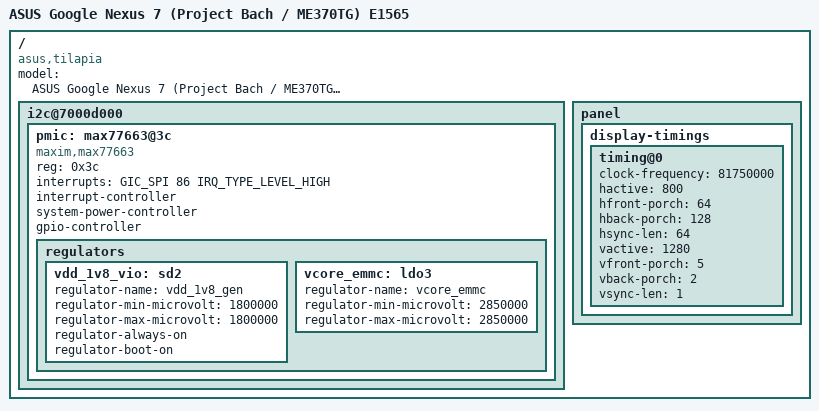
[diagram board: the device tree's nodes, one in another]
// SPDX-License-Identifier: GPL-2.0
/dts-v1/;

#include "tegra30-asus-grouper-common.dtsi"

/ {
	model = "ASUS Google Nexus 7 (Project Bach / ME370TG) E1565";
	compatible = "asus,tilapia", "nvidia,tegra30";

	i2c@7000d000 {
		pmic: max77663@3c {
			compatible = "maxim,max77663";
			reg = <0x3c>;

			interrupts = <GIC_SPI 86 IRQ_TYPE_LEVEL_HIGH>;
			#interrupt-cells = <2>;
			interrupt-controller;

			system-power-controller;

			#gpio-cells = <2>;
			gpio-controller;

			regulators {
				vdd_1v8_vio: sd2 {
					regulator-name = "vdd_1v8_gen";
					regulator-min-microvolt = <1800000>;
					regulator-max-microvolt = <1800000>;
					regulator-always-on;
					regulator-boot-on;
				};

				/* eMMC VDD */
				vcore_emmc: ldo3 {
					regulator-name = "vcore_emmc";
					regulator-min-microvolt = <2850000>;
					regulator-max-microvolt = <2850000>;
				};
			};
		};
	};

	panel {
		display-timings {
			timing@0 {
				/* 1280x800@60Hz */
				clock-frequency = <81750000>;

				hactive = <800>;
				hfront-porch = <64>;
				hback-porch = <128>;
				hsync-len = <64>;

				vactive = <1280>;
				vfront-porch = <5>;
				vback-porch = <2>;
				vsync-len = <1>;
			};
		};
	};
};
